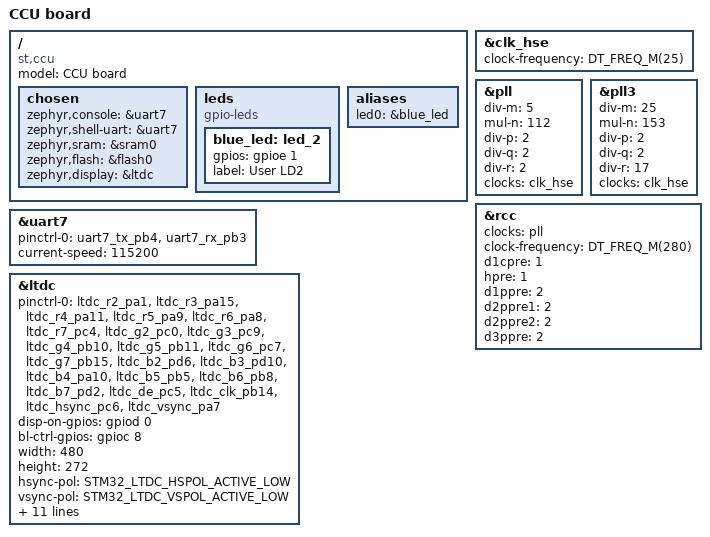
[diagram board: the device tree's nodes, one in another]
/*
 * Copyright (c) 2022 Byte-Lab d.o.o. <dev@byte-lab.com>
 *
 * SPDX-License-Identifier: Apache-2.0
 */

/dts-v1/;
#include <st/h7/stm32h7a3Xi.dtsi>
#include <st/h7/stm32h7a3v(g-i)tx-pinctrl.dtsi>
#include <zephyr/dt-bindings/display/stm32_ltdc.h>

/ {
    model = "CCU board";
    compatible = "st,ccu";

    chosen {
        zephyr,console = &uart7;
        zephyr,shell-uart = &uart7;
        zephyr,sram = &sram0;
        zephyr,flash = &flash0;
        zephyr,display = &ltdc;
    };

    leds {
        compatible = "gpio-leds";
        blue_led: led_2 {
            gpios = <&gpioe 1 GPIO_ACTIVE_HIGH>;
            label = "User LD2";
        };
    };

    aliases {
        led0 = &blue_led;
    };
};

&clk_hse {
    clock-frequency = <DT_FREQ_M(25)>;
    status = "okay";
};

&pll {
    div-m = <5>;
    mul-n = <112>;
    div-p = <2>;
    div-q = <2>;
    div-r = <2>;
    clocks = <&clk_hse>;
    status = "okay";
};

/* PLLR is used for outputting 9 MHz pixel clock for LTDC */
&pll3 {
    div-m = <25>;
    mul-n = <153>;
    div-p = <2>;
    div-q = <2>;
    div-r = <17>;
    clocks = <&clk_hse>;
    status = "okay";
};

&rcc {
    clocks = <&pll>;
    clock-frequency = <DT_FREQ_M(280)>;
    d1cpre = <1>;
    hpre = <1>;
    d1ppre = <2>;
    d2ppre1 = <2>;
    d2ppre2 = <2>;
    d3ppre = <2>;
};

&uart7 {
    pinctrl-0 = <&uart7_tx_pb4 &uart7_rx_pb3>;
    pinctrl-names = "default";
    current-speed = <115200>;
    status = "okay";
};


&ltdc {
    pinctrl-0 = <&ltdc_r2_pa1 &ltdc_r3_pa15 &ltdc_r4_pa11
             &ltdc_r5_pa9 &ltdc_r6_pa8 &ltdc_r7_pc4
             &ltdc_g2_pc0 &ltdc_g3_pc9 &ltdc_g4_pb10
             &ltdc_g5_pb11 &ltdc_g6_pc7 &ltdc_g7_pb15
             &ltdc_b2_pd6 &ltdc_b3_pd10 &ltdc_b4_pa10
             &ltdc_b5_pb5 &ltdc_b6_pb8 &ltdc_b7_pd2
             &ltdc_de_pc5 &ltdc_clk_pb14 &ltdc_hsync_pc6
             &ltdc_vsync_pa7>;
    pinctrl-names = "default";
    disp-on-gpios = <&gpiod 0 GPIO_ACTIVE_HIGH>;
    bl-ctrl-gpios = <&gpioc 8 GPIO_ACTIVE_HIGH>;
    status = "okay";

    width = <480>;
    height = <272>;
    hsync-pol = <STM32_LTDC_HSPOL_ACTIVE_LOW>;
    vsync-pol = <STM32_LTDC_VSPOL_ACTIVE_LOW>;
    de-pol = <STM32_LTDC_DEPOL_ACTIVE_LOW>;
    pclk-pol = <STM32_LTDC_PCPOL_ACTIVE_LOW>;
    hsync-duration = <1>;
    vsync-duration = <10>;
    hbp-duration = <43>;
    vbp-duration = <12>;
    hfp-duration = <8>;
    vfp-duration = <4>;
    def-back-color-red = <0xFF>;
    def-back-color-green = <0xFF>;
    def-back-color-blue = <0xFF>;
};
 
